# M251_v1 register map
File version: 1.0
Registers are 32-bit, read-write, reset 0x0 unless marked. A register's access mark holds for its fields unless they carry their own. Offsets are from the block's base; [hi:lo] are bit positions; {n}, {i} and the like mark numbered series.

## CRC — CRC Register Map
Base 0x40031000
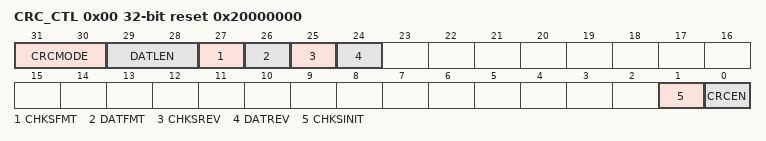
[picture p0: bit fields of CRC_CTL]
0x00 CRC_CTL reset 0x20000000 — CRC Control Register
  [31:30] CRCMODE — CRC Polynomial Mode. This field indicates the CRC operation polynomial mode.
    0=CRC-CCITT Polynomial mode; 1=CRC-8 Polynomial mode; 2=CRC-16 Polynomial mode; 3=CRC-32 Polynomial mode
  [29:28] DATLEN — CPU Write Data Length. This field indicates the write data length. Note: When the write data length is 8-bit mode, the valid data in CRC_DAT register is only DATA[7:0] bits; if the write data length is 16-bit mode, the valid data in CRC_DAT register is only DATA[15:0].
    0=Data length is 8-bit mode; 1=Data length is 16-bit mode. Data length is 32-bit mode
  [27] CHKSFMT — Checksum 1's Complement. This bit is used to enable the 1's complement function for checksum result in CRC_CHECKSUM register.
    0=1's complement for CRC checksum Disabled; 1=1's complement for CRC checksum Enabled
  [26] DATFMT — Write Data 1's Complement. This bit is used to enable the 1's complement function for write data value in CRC_DAT register.
    0=1's complement for CRC writes data in Disabled; 1=1's complement for CRC writes data in Enabled
  [25] CHKSREV — Checksum Bit Order Reverse. This bit is used to enable the bit order reverse function for checksum result in CRC_CHECKSUM register. Note: If the checksum result is 0xDD7B0F2E, the bit order reverse for CRC checksum is 0x74F0DEBB.
    0=Bit order reverse for CRC checksum Disabled; 1=Bit order reverse for CRC checksum Enabled
  [24] DATREV — Write Data Bit Order Reverse. This bit is used to enable the bit order reverse function per byte for write data value in CRC_DAT register. Note: If the write data is 0xAABBCCDD, the bit order reverse for CRC write data in is 0x55DD33BB.
    0=Bit order reversed for CRC write data in Disabled; 1=Bit order reversed for CRC write data in Enabled (per byte)
  [1] CHKSINIT — Checksum Initialization. Note: This bit will be cleared automatically.
    0=No effect; 1=Initial checksum value by auto reload CRC_SEED register value to CRC_CHECKSUM register value
  [0] CRCEN — CRC Channel Enable Bit
    0=No effect; 1=CRC operation Enabled
0x04 CRC_DAT — CRC Write Data Register
  [31:0] DATA — CRC Write Data Bits. User can write data directly by CPU mode or use PDMA function to write data to this field to perform CRC operation. Note: When the write data length is 8-bit mode, the valid data in CRC_DAT register is only DATA[7:0] bits; if the write data length is 16-bit mode, the valid data in CRC_DAT register is only DATA[15:0].
0x08 CRC_SEED reset 0xFFFFFFFF
  [31:0] SEED — CRC Seed Value. This field indicates the CRC seed value. Note: This field will be reloaded as checksum initial value (CRC_CHECKSUM register) after perform CHKSINIT (CRC_CTL[1]).
0x0C CRC_CHECKSUM ro reset 0xFFFFFFFF
  [31:0] CHECKSUM — CRC Checksum Results. This field indicates the CRC checksum result.

## DAC — DAC Register Map
Base 0x40047000
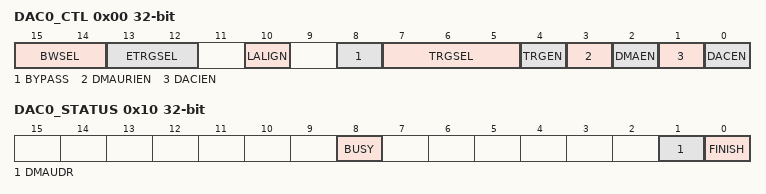
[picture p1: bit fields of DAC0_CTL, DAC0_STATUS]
0x00 DAC0_CTL — DAC0 Control Register
  [15:14] BWSEL — DAC Data Bit-width Selection
    0=data is 12 bits; 1=data is 8 bits
  [13:12] ETRGSEL — External Pin Trigger Selection
    0=Low level trigger; 1=High level trigger; 2=Falling edge trigger; 3=Rising edge trigger
  [10] LALIGN — DAC Data Left-aligned Enabled Bit. Note: Only for 12 bit mode.
    0=Right alignment; 1=Left alignment
  [8] BYPASS — Bypass Buffer Mode
    0=Output voltage buffer Enabled; 1=Output voltage buffer Disabled
  [7:5] TRGSEL — Trigger Source Selection
    0=Software trigger; 1=External pin DAC0_ST trigger; {v}=Timer {v-2} trigger (v=2..5)
  [4] TRGEN — Trigger Mode Enable Bit
    0=DAC event trigger mode Disabled; 1=DAC event trigger mode Enabled
  [3] DMAURIEN — DMA Under-run Interrupt Enable Bit
    0=DMA interrupt Disabled; 1=DMA under-run interrupt Enabled
  [2] DMAEN — DMA Mode Enable Bit
    0=DMA mode Disabled; 1=DMA mode Enabled
  [1] DACIEN — DAC Interrupt Enable Bit
    0=DAC interrupt Disabled; 1=DAC interrupt Enabled
  [0] DACEN — DAC Enable Bit
    0=DAC Disabled; 1=DAC Enabled
0x04 DAC0_SWTRG — DAC0 Software Trigger Control Register
  [0] SWTRG — Software Trigger. Note: User writes this bit to generate one shot pulse and it is cleared to 0 by hardware automatically; reading this bit will always get 0.
    0=Software trigger Disabled; 1=Software trigger Enabled
0x08 DAC0_DAT — DAC0 Data Holding Register
  [15:0] DACDAT — DAC 12-bit Holding Data. The unused bits (DAC0_DAT[3:0] in left-alignment mode and DAC0_DAT[15:12] in right alignment mode) are ignored by DAC controller hardware. 12 bit left alignment: user has to load data into DAC0_DAT[15:4] bits. 12 bit right alignment: user has to load data into DAC0_DAT[11:0] bits. DAC 8-bit Holding Data. The unused bits DAC0_DAT[15:8] are ignored by DAC controller hardware. Note: Conversion data and DAC output data is 12-bit.
0x0C DAC0_DATOUT ro — DAC0 Data Output Register
  [11:0] DATOUT — DAC 12-bit Output Data. These bits are current digital data for DAC output conversion. It is loaded from DAC_DAT register and user cannot write it directly.
0x10 DAC0_STATUS
  [8] BUSY ro — DAC Busy Flag (Read Only)
    0=DAC is ready for next conversion; 1=DAC is busy in conversion
  [1] DMAUDR — DMA Under-run Interrupt Flag. Note: User writes 1 to clear this bit.
    0=No DMA under-run error condition occurred; 1=DMA under-run error condition occurred
  [0] FINISH — DAC Conversion Complete Finish Flag. Note: This bit is set to 1 when conversion time counter counts to SETTLET. It is cleared to 0 when DAC starts a new conversion. User writes 1 to clear this bit to 0.
    0=DAC is in conversion state; 1=DAC conversion finish
0x14 DAC0_TCTL — DAC0 Timing Control Register
  [9:0] SETTLET — DAC Output Settling Time. User software needs to write appropriate value to these bits to meet DAC conversion settling time base on PCLK (APB clock) speed. For example, DAC controller clock speed is 50 MHz and DAC conversion setting time is 1 us, SETTLET value must be greater than 0x32.

## OPA — OPA Register Map
Base 0x40046000
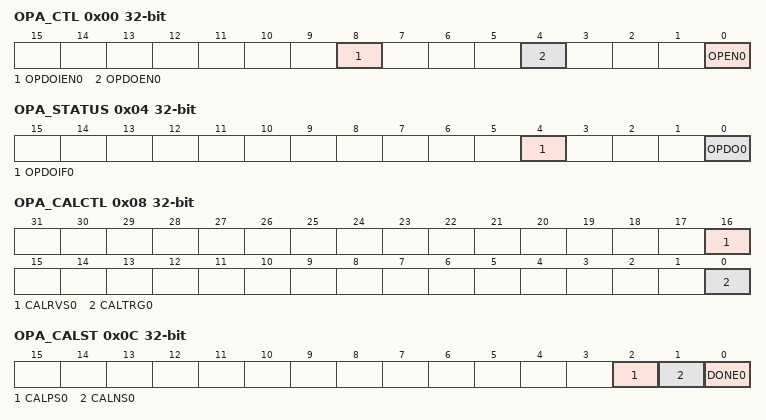
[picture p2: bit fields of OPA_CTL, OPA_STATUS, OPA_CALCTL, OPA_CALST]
0x00 OPA_CTL — OP Amplifier Control Register
  [8] OPDOIEN0 — OP Amplifier 0 Schmitt Trigger Digital Output Interrupt Enable Bit. Note: The OPDOIF0 interrupt flag is set by hardware whenever the OP amplifier 0 Schmitt trigger non-inverting buffer digital output changes state, in the meanwhile, if OPDOIEN0 is set to 1, a comparator interrupt request is generated.
    0=OP Amplifier 0 digital output interrupt function Disabled; 1=OP Amplifier 0 digital output interrupt function Enabled
  [4] OPDOEN0 — OP Amplifier 0 Schmitt Trigger Non-inverting Buffer Enable Bit
    0=Disable OP amplifier0 schmitt trigger non-invert buffer; 1=Enable OP amplifier0 schmitt trigger non-invert buffer
  [0] OPEN0 — OP Amplifier 0 Enable Bit. Note: OP Amplifier 0 output needs wait stable 20μs after OPEN0 is set.
    0=OP amplifier0 Disabled; 1=OP amplifier0 Enabled
0x04 OPA_STATUS — OP Amplifier Status Register
  [4] OPDOIF0 — OP Amplifier 0 Schmitt Trigger Digital Output Interrupt Flag. OPDOIF0 interrupt flag is set by hardware whenever the OP amplifier 0 Schmitt trigger non-inverting buffer digital output changes state. This bit is cleared by writing 1 to it.
  [0] OPDO0 — OP Amplifier 0 Digital Output
0x08 OPA_CALCTL — OP Amplifier Calibration Control Register
  [16] CALRVS0 — OPA0 Calibration Reference Voltage Selection
    0=VREF is; 1=VREF from high vcm to low vcm
  [0] CALTRG0 — OP Amplifier 0 Calibration Trigger Bit. Note: Before this bit is enabled, OPEN0 should be set in advance.
    0=OP amplifier 0 calibration is stopped; hardware auto clear; 1=OP amplifier 0 calibration is started
0x0C OPA_CALST ro — OP Amplifier Calibration Status Register
  [2] CALPS0 — OP Amplifier 0 Calibration Result Status for PMOS
    0=Pass; 1=Fail
  [1] CALNS0 — OP Amplifier 0 Calibration Result Status for NMOS
    0=Pass; 1=Fail
  [0] DONE0 — OP Amplifier 0 Calibration Done Status
    0=Calibrating; 1=Calibration Done
